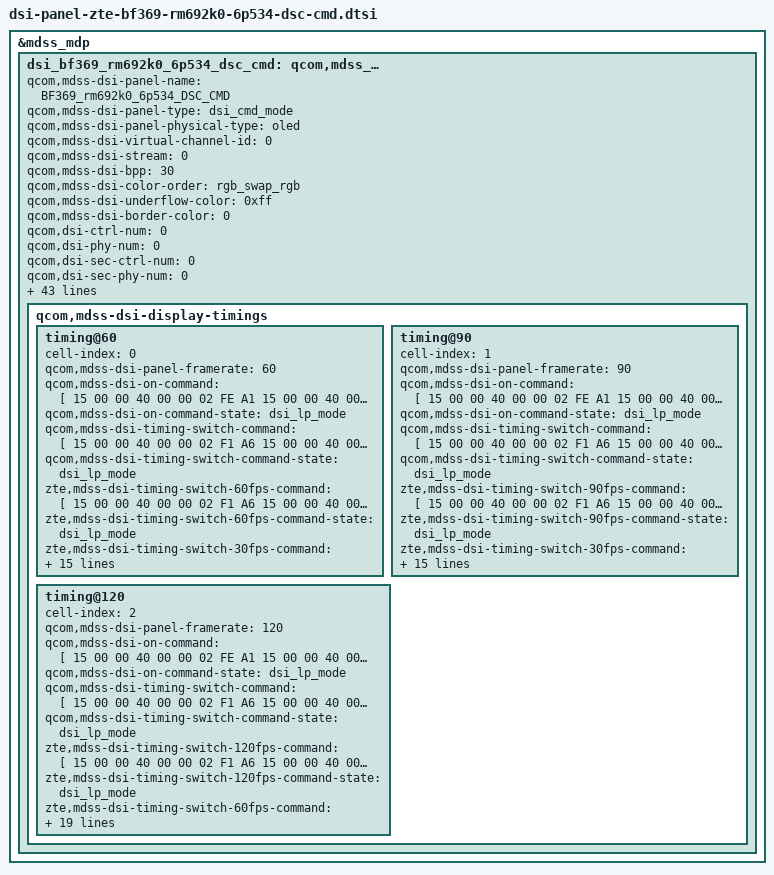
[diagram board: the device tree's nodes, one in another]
// SPDX-License-Identifier: BSD-3-Clause
/*
 * Copyright (c) 2023-2024 Qualcomm Innovation Center, Inc. All rights reserved.
 */

&mdss_mdp {
	dsi_bf369_rm692k0_6p534_dsc_cmd: qcom,mdss_dsi_bf369_rm692k0_6p534_dsc_cmd {
		qcom,mdss-dsi-panel-name =
				"BF369_rm692k0_6p534_DSC_CMD";
		qcom,mdss-dsi-panel-type = "dsi_cmd_mode";
		qcom,mdss-dsi-panel-physical-type = "oled";
		qcom,mdss-dsi-virtual-channel-id = <0>;
		qcom,mdss-dsi-stream = <0>;
		qcom,mdss-dsi-bpp = <30>;
		qcom,mdss-dsi-color-order = "rgb_swap_rgb";
		qcom,mdss-dsi-underflow-color = <0xff>;
		qcom,mdss-dsi-border-color = <0>;
		qcom,dsi-ctrl-num = <0>;
		qcom,dsi-phy-num = <0>;
		qcom,dsi-sec-ctrl-num = <0>;
		qcom,dsi-sec-phy-num = <0>;
		qcom,mdss-dsi-traffic-mode = "burst_mode";
		qcom,mdss-dsi-lane-map = "lane_map_0123";
		qcom,mdss-dsi-bllp-eof-power-mode;
		qcom,mdss-dsi-bllp-power-mode;
		qcom,mdss-dsi-lane-0-state;
		qcom,mdss-dsi-lane-1-state;
		qcom,mdss-dsi-lane-2-state;
		qcom,mdss-dsi-lane-3-state;
		qcom,mdss-dsi-lp11-init;
		qcom,mdss-dsi-tx-eot-append;
		qcom,mdss-dsi-dma-trigger = "trigger_sw";
		qcom,mdss-dsi-mdp-trigger = "none";
		qcom,mdss-dsi-reset-sequence = <1 10>, <0 10>, <1 40>;
		qcom,mdss-dsi-te-pin-select = <1>;
		qcom,mdss-dsi-te-dcs-command = <1>;
		qcom,mdss-dsi-te-check-enable;
		qcom,mdss-dsi-te-using-te-pin;
		qcom,mdss-dsi-bl-min-level = <1>;
		qcom,mdss-dsi-bl-max-level = <4095>;
		qcom,mdss-dsi-bl-pmic-control-type = "bl_ctrl_dcs";
		qcom,mdss-dsi-panel-hdr-enabled;
		qcom,mdss-dsi-panel-hdr-color-primaries = <14500 15500 34015
			15980 13030 34670 6950 2565>;
		qcom,mdss-dsi-panel-peak-brightness = <6680000>;
		qcom,mdss-dsi-panel-blackness-level = <20>;
		qcom,mdss-pan-physical-width-dimension = <72>;
		qcom,mdss-pan-physical-height-dimension = <158>;
		qcom,bl-dcs-cmd-state = "dsi_lp_mode";
		qcom,bl-dsc-cmd-state = "dsi_lp_mode";
		qcom,mdss-disable-cesta-hw-sleep;
		qcom,mdss-dsi-display-timings {
			timing@60 {
				cell-index = <0>;
				qcom,mdss-dsi-panel-framerate = <60>;
				#include "dsi-panel-zte-bf369-rm692k0-6p534-dsc-cmd-common.dtsi"
				qcom,mdss-dsi-on-command = [
					15 00 00 40 00 00 02 FE A1
					15 00 00 40 00 00 02 50 20
					15 00 00 40 00 00 02 FE A3
					15 00 00 40 00 00 02 00 01
					15 00 00 40 00 00 02 FE D0
					15 00 00 40 00 00 02 86 23
					15 00 00 40 00 00 02 84 23
					15 00 00 40 00 00 02 FE 99
					15 00 00 40 00 00 02 1B 23
					15 00 00 40 00 00 02 FE 44
					15 00 00 40 00 00 02 41 10
					15 00 00 40 00 00 02 3D 08
					15 00 00 40 00 00 02 08 32
					15 00 00 40 00 00 02 17 00
					15 00 00 40 00 00 02 18 06
					15 00 00 40 00 00 02 19 0F
					15 00 00 40 00 00 02 1F 44
					15 00 00 40 00 00 02 20 41
					15 00 00 40 00 00 02 FE FF
					15 00 00 40 00 00 02 63 1C
					15 00 00 40 00 00 02 64 1C
					15 00 00 40 00 00 02 65 1C
					15 00 00 40 00 00 02 66 1C
					15 00 00 40 00 00 02 6B 00
					15 00 00 40 00 00 02 6C 00
					15 00 00 40 00 00 02 6D 00
					15 00 00 40 00 00 02 6E 00
					15 00 00 40 00 00 02 FE E3
					15 00 00 00 00 00 02 73 80
					/* vesa */
					15 00 00 40 00 00 02 FE D2
					15 00 00 40 00 00 02 97 08
					15 00 00 40 00 00 02 FE A1
					15 00 00 40 00 00 02 75 B3
					15 00 00 40 00 00 02 FE D2
					15 00 00 40 00 00 02 36 11
					15 00 00 40 00 00 02 39 ab
					15 00 00 40 00 00 02 3a 30
					15 00 00 40 00 00 02 3b 80
					15 00 00 40 00 00 02 3d 0a
					15 00 00 40 00 00 02 3f bc
					15 00 00 40 00 00 02 40 04
					15 00 00 40 00 00 02 41 94
					15 00 00 40 00 00 02 42 00
					15 00 00 40 00 00 02 43 0c
					15 00 00 40 00 00 02 44 02
					15 00 00 40 00 00 02 45 4a
					15 00 00 40 00 00 02 46 02
					15 00 00 40 00 00 02 47 4a
					15 00 00 40 00 00 02 48 02
					15 00 00 40 00 00 02 49 00
					15 00 00 40 00 00 02 4a 02
					15 00 00 40 00 00 02 4b 26
					15 00 00 40 00 00 02 4d 20
					15 00 00 40 00 00 02 4e 01
					15 00 00 40 00 00 02 4f 2c
					15 00 00 40 00 00 02 50 00
					15 00 00 40 00 00 02 51 08
					15 00 00 40 00 00 02 53 0c
					15 00 00 40 00 00 02 54 08
					15 00 00 40 00 00 02 55 bb
					15 00 00 40 00 00 02 56 07
					15 00 00 40 00 00 02 58 c9
					15 00 00 40 00 00 02 59 18
					15 00 00 40 00 00 02 5a 00
					15 00 00 40 00 00 02 5b 10
					15 00 00 40 00 00 02 5c f0
					15 00 00 40 00 00 02 5d 07
					15 00 00 40 00 00 02 5e 10
					15 00 00 40 00 00 02 5f 20
					15 00 00 40 00 00 02 60 00
					15 00 00 40 00 00 02 61 06
					15 00 00 40 00 00 02 62 0f
					15 00 00 40 00 00 02 63 0f
					15 00 00 40 00 00 02 64 33
					15 00 00 40 00 00 02 65 0e
					15 00 00 40 00 00 02 66 1c
					15 00 00 40 00 00 02 67 2a
					15 00 00 40 00 00 02 68 38
					15 00 00 40 00 00 02 69 46
					15 00 00 40 00 00 02 6a 54
					15 00 00 40 00 00 02 6b 62
					15 00 00 40 00 00 02 6c 69
					15 00 00 40 00 00 02 6d 70
					15 00 00 40 00 00 02 6e 77
					15 00 00 40 00 00 02 6f 79
					15 00 00 40 00 00 02 70 7b
					15 00 00 40 00 00 02 71 7d
					15 00 00 40 00 00 02 72 7e
					15 00 00 40 00 00 02 73 02
					15 00 00 40 00 00 02 74 02
					15 00 00 40 00 00 02 75 22
					15 00 00 40 00 00 02 76 00
					15 00 00 40 00 00 02 77 2a
					15 00 00 40 00 00 02 78 40
					15 00 00 40 00 00 02 79 2a
					15 00 00 40 00 00 02 7a be
					15 00 00 40 00 00 02 7b 3a
					15 00 00 40 00 00 02 7c fc
					15 00 00 40 00 00 02 7d 3a
					15 00 00 40 00 00 02 7e fa
					15 00 00 40 00 00 02 7f 3a
					15 00 00 40 00 00 02 80 f8
					15 00 00 40 00 00 02 81 3b
					15 00 00 40 00 00 02 82 38
					15 00 00 40 00 00 02 83 3b
					15 00 00 40 00 00 02 84 78
					15 00 00 40 00 00 02 85 3b
					15 00 00 40 00 00 02 86 b6
					15 00 00 40 00 00 02 87 4b
					15 00 00 40 00 00 02 88 f6
					15 00 00 40 00 00 02 89 4c
					15 00 00 40 00 00 02 8a 34
					15 00 00 40 00 00 02 8b 4c
					15 00 00 40 00 00 02 8c 74
					15 00 00 40 00 00 02 8d 5c
					15 00 00 40 00 00 02 8e 74
					15 00 00 40 00 00 02 8f 8c
					15 00 00 40 00 00 02 90 f4
					15 00 00 40 00 00 02 91 00
					15 00 00 40 00 00 02 92 00
					15 00 00 40 00 00 02 93 00
					15 00 00 40 00 00 02 94 00
					15 00 00 40 00 00 02 95 00
					15 00 00 00 00 00 02 96 00
					/* add */
					15 00 00 00 00 00 02 FE A1
					15 00 00 00 00 00 02 58 67
					/* init code */
					15 00 00 00 00 00 02 FE 00
					15 00 00 00 00 00 02 2F 0C
					15 00 00 00 00 00 02 FA 01
					15 00 00 00 00 00 02 C2 08
					15 00 00 00 00 00 02 35 00
					39 00 00 00 00 00 03 51 00 00
					05 00 00 00 64 00 01 11
					05 00 00 00 14 00 01 29
					/* fps 60 */
					15 00 00 40 00 00 02 F1 A6
					15 00 00 40 00 00 02 FE 00
					15 00 00 40 00 00 02 6A 10
					15 00 00 40 00 00 02 8A 12
					15 00 00 40 00 00 02 FE 98
					15 00 00 40 00 00 02 37 92
					15 00 00 40 00 00 02 3B 0A
					15 00 00 40 00 00 02 FE 45
					15 00 00 40 00 00 02 B5 83
					15 00 00 40 00 00 02 B6 C0
					15 00 00 40 00 00 02 B7 30
					15 00 00 40 00 00 02 B8 5C
					15 00 00 40 00 00 02 B9 44
					15 00 00 40 00 00 02 BB 06
					15 00 00 40 00 00 02 BA 05
					15 00 00 40 00 00 02 BC 00
					15 00 00 40 00 00 02 BD 09
					15 00 00 00 12 00 02 FB AA
					15 00 00 00 00 00 02 FE 00
					];
				qcom,mdss-dsi-on-command-state = "dsi_lp_mode";
				qcom,mdss-dsi-timing-switch-command = [
					/* fps 60 */
					15 00 00 40 00 00 02 F1 A6
					15 00 00 40 00 00 02 FE 00
					15 00 00 40 00 00 02 6A 10
					15 00 00 40 00 00 02 8A 12
					15 00 00 40 00 00 02 FE 98
					15 00 00 40 00 00 02 37 92
					15 00 00 40 00 00 02 3B 0A
					15 00 00 40 00 00 02 FE 45
					15 00 00 40 00 00 02 B5 83
					15 00 00 40 00 00 02 B6 C0
					15 00 00 40 00 00 02 B7 30
					15 00 00 40 00 00 02 B8 5C
					15 00 00 40 00 00 02 B9 44
					15 00 00 40 00 00 02 BB 06
					15 00 00 40 00 00 02 BA 05
					15 00 00 40 00 00 02 BC 00
					15 00 00 40 00 00 02 BD 09
					15 00 00 00 12 00 02 FB AA
					15 00 00 00 00 00 02 FE 00
					];
				qcom,mdss-dsi-timing-switch-command-state = "dsi_lp_mode";
				zte,mdss-dsi-timing-switch-60fps-command = [
					/* fps 60 */
					15 00 00 40 00 00 02 F1 A6
					15 00 00 40 00 00 02 FE 00
					15 00 00 40 00 00 02 6A 10
					15 00 00 40 00 00 02 8A 12
					15 00 00 40 00 00 02 FE 98
					15 00 00 40 00 00 02 37 92
					15 00 00 40 00 00 02 3B 0A
					15 00 00 40 00 00 02 FE 45
					15 00 00 40 00 00 02 B5 83
					15 00 00 40 00 00 02 B6 C0
					15 00 00 40 00 00 02 B7 30
					15 00 00 40 00 00 02 B8 5C
					15 00 00 40 00 00 02 B9 44
					15 00 00 40 00 00 02 BB 06
					15 00 00 40 00 00 02 BA 05
					15 00 00 40 00 00 02 BC 00
					15 00 00 40 00 00 02 BD 09
					15 00 00 00 12 00 02 FB AA
					15 00 00 00 00 00 02 FE 00
				];
				zte,mdss-dsi-timing-switch-60fps-command-state = "dsi_lp_mode";
				zte,mdss-dsi-timing-switch-30fps-command = [
					/* fps 30 */
					15 00 00 40 00 00 02 F1 A6
					15 00 00 40 00 00 02 FE 00
					15 00 00 40 00 00 02 6A 10
					15 00 00 40 00 00 02 8A 1A
					15 00 00 40 00 00 02 FE 98
					15 00 00 40 00 00 02 37 92
					15 00 00 40 00 00 02 3B 0A
					15 00 00 40 00 00 02 FE 45
					15 00 00 40 00 00 02 B5 83
					15 00 00 40 00 00 02 B6 C0
					15 00 00 40 00 00 02 B7 30
					15 00 00 40 00 00 02 B8 5C
					15 00 00 40 00 00 02 B9 44
					15 00 00 40 00 00 02 BB 06
					15 00 00 40 00 00 02 BA 05
					15 00 00 40 00 00 02 BC 00
					15 00 00 40 00 00 02 BD 09
					15 00 00 00 12 00 02 FB AA
					15 00 00 00 00 00 02 FE 00
				];
				zte,mdss-dsi-timing-switch-30fps-command-state = "dsi_lp_mode";
				zte,mdss-dsi-timing-switch-10fps-command = [
					/* fps 10 */
					15 00 00 40 00 00 02 F1 A6
					15 00 00 40 00 00 02 FE 00
					15 00 00 40 00 00 02 6A 10
					15 00 00 40 00 00 02 8A 1B
					15 00 00 40 00 00 02 FE 98
					15 00 00 40 00 00 02 37 92
					15 00 00 40 00 00 02 3B 0A
					15 00 00 40 00 00 02 FE 45
					15 00 00 40 00 00 02 B5 83
					15 00 00 40 00 00 02 B6 C0
					15 00 00 40 00 00 02 B7 30
					15 00 00 40 00 00 02 B8 5C
					15 00 00 40 00 00 02 B9 44
					15 00 00 40 00 00 02 BB 06
					15 00 00 40 00 00 02 BA 05
					15 00 00 40 00 00 02 BC 00
					15 00 00 40 00 00 02 BD 09
					15 00 00 00 12 00 02 FB AA
					15 00 00 00 00 00 02 FE 00
				];
				zte,mdss-dsi-timing-switch-10fps-command-state = "dsi_lp_mode";
				zte,mdss-dsi-timing-switch-5fps-command = [
					/* fps 1 */
					15 00 00 40 00 00 02 F1 A6
					15 00 00 40 00 00 02 FE 00
					15 00 00 40 00 00 02 6A 10
					15 00 00 40 00 00 02 8A 1C
					15 00 00 40 00 00 02 FE 98
					15 00 00 40 00 00 02 37 92
					15 00 00 40 00 00 02 3B 0A
					15 00 00 40 00 00 02 FE 45
					15 00 00 40 00 00 02 B5 83
					15 00 00 40 00 00 02 B6 C0
					15 00 00 40 00 00 02 B7 30
					15 00 00 40 00 00 02 B8 5C
					15 00 00 40 00 00 02 B9 44
					15 00 00 40 00 00 02 BB 06
					15 00 00 40 00 00 02 BA 05
					15 00 00 40 00 00 02 BC 00
					15 00 00 40 00 00 02 BD 09
					15 00 00 00 12 00 02 FB AA
					15 00 00 00 00 00 02 FE 00
				];
				zte,mdss-dsi-timing-switch-5fps-command-state = "dsi_lp_mode";
				zte,mdss-dsi-timing-switch-1fps-command = [
					/* fps 1 */
					15 00 00 40 00 00 02 F1 A6
					15 00 00 40 00 00 02 FE 00
					15 00 00 40 00 00 02 6A 10
					15 00 00 40 00 00 02 8A 1D
					15 00 00 40 00 00 02 FE 98
					15 00 00 40 00 00 02 37 92
					15 00 00 40 00 00 02 3B 0A
					15 00 00 40 00 00 02 FE 45
					15 00 00 40 00 00 02 B5 83
					15 00 00 40 00 00 02 B6 C0
					15 00 00 40 00 00 02 B7 30
					15 00 00 40 00 00 02 B8 5C
					15 00 00 40 00 00 02 B9 45
					15 00 00 40 00 00 02 BB 06
					15 00 00 40 00 00 02 BA 05
					15 00 00 40 00 00 02 BC 00
					15 00 00 40 00 00 02 BD 09
					15 00 00 00 12 00 02 FB AA
					15 00 00 00 00 00 02 FE 00
				];
				zte,mdss-dsi-timing-switch-1fps-command-state = "dsi_lp_mode";
			};
			timing@90 {
				cell-index = <1>;
				qcom,mdss-dsi-panel-framerate = <90>;
				#include "dsi-panel-zte-bf369-rm692k0-6p534-dsc-cmd-common.dtsi"
				qcom,mdss-dsi-on-command = [
					15 00 00 40 00 00 02 FE A1
					15 00 00 40 00 00 02 50 20
					15 00 00 40 00 00 02 FE A3
					15 00 00 40 00 00 02 00 01
					15 00 00 40 00 00 02 FE D0
					15 00 00 40 00 00 02 86 23
					15 00 00 40 00 00 02 84 23
					15 00 00 40 00 00 02 FE 99
					15 00 00 40 00 00 02 1B 23
					15 00 00 40 00 00 02 FE 44
					15 00 00 40 00 00 02 41 10
					15 00 00 40 00 00 02 3D 08
					15 00 00 40 00 00 02 08 32
					15 00 00 40 00 00 02 17 00
					15 00 00 40 00 00 02 18 06
					15 00 00 40 00 00 02 19 0F
					15 00 00 40 00 00 02 1F 44
					15 00 00 40 00 00 02 20 41
					15 00 00 40 00 00 02 FE FF
					15 00 00 40 00 00 02 63 1C
					15 00 00 40 00 00 02 64 1C
					15 00 00 40 00 00 02 65 1C
					15 00 00 40 00 00 02 66 1C
					15 00 00 40 00 00 02 6B 00
					15 00 00 40 00 00 02 6C 00
					15 00 00 40 00 00 02 6D 00
					15 00 00 40 00 00 02 6E 00
					15 00 00 40 00 00 02 FE E3
					15 00 00 00 00 00 02 73 80
					/* vesa */
					15 00 00 40 00 00 02 FE D2
					15 00 00 40 00 00 02 97 08
					15 00 00 40 00 00 02 FE A1
					15 00 00 40 00 00 02 75 B3
					15 00 00 40 00 00 02 FE D2
					15 00 00 40 00 00 02 36 11
					15 00 00 40 00 00 02 39 ab
					15 00 00 40 00 00 02 3a 30
					15 00 00 40 00 00 02 3b 80
					15 00 00 40 00 00 02 3d 0a
					15 00 00 40 00 00 02 3f bc
					15 00 00 40 00 00 02 40 04
					15 00 00 40 00 00 02 41 94
					15 00 00 40 00 00 02 42 00
					15 00 00 40 00 00 02 43 0c
					15 00 00 40 00 00 02 44 02
					15 00 00 40 00 00 02 45 4a
					15 00 00 40 00 00 02 46 02
					15 00 00 40 00 00 02 47 4a
					15 00 00 40 00 00 02 48 02
					15 00 00 40 00 00 02 49 00
					15 00 00 40 00 00 02 4a 02
					15 00 00 40 00 00 02 4b 26
					15 00 00 40 00 00 02 4d 20
					15 00 00 40 00 00 02 4e 01
					15 00 00 40 00 00 02 4f 2c
					15 00 00 40 00 00 02 50 00
					15 00 00 40 00 00 02 51 08
					15 00 00 40 00 00 02 53 0c
					15 00 00 40 00 00 02 54 08
					15 00 00 40 00 00 02 55 bb
					15 00 00 40 00 00 02 56 07
					15 00 00 40 00 00 02 58 c9
					15 00 00 40 00 00 02 59 18
					15 00 00 40 00 00 02 5a 00
					15 00 00 40 00 00 02 5b 10
					15 00 00 40 00 00 02 5c f0
					15 00 00 40 00 00 02 5d 07
					15 00 00 40 00 00 02 5e 10
					15 00 00 40 00 00 02 5f 20
					15 00 00 40 00 00 02 60 00
					15 00 00 40 00 00 02 61 06
					15 00 00 40 00 00 02 62 0f
					15 00 00 40 00 00 02 63 0f
					15 00 00 40 00 00 02 64 33
					15 00 00 40 00 00 02 65 0e
					15 00 00 40 00 00 02 66 1c
					15 00 00 40 00 00 02 67 2a
					15 00 00 40 00 00 02 68 38
					15 00 00 40 00 00 02 69 46
					15 00 00 40 00 00 02 6a 54
					15 00 00 40 00 00 02 6b 62
					15 00 00 40 00 00 02 6c 69
					15 00 00 40 00 00 02 6d 70
					15 00 00 40 00 00 02 6e 77
					15 00 00 40 00 00 02 6f 79
					15 00 00 40 00 00 02 70 7b
					15 00 00 40 00 00 02 71 7d
					15 00 00 40 00 00 02 72 7e
					15 00 00 40 00 00 02 73 02
					15 00 00 40 00 00 02 74 02
					15 00 00 40 00 00 02 75 22
					15 00 00 40 00 00 02 76 00
					15 00 00 40 00 00 02 77 2a
					15 00 00 40 00 00 02 78 40
					15 00 00 40 00 00 02 79 2a
					15 00 00 40 00 00 02 7a be
					15 00 00 40 00 00 02 7b 3a
					15 00 00 40 00 00 02 7c fc
					15 00 00 40 00 00 02 7d 3a
					15 00 00 40 00 00 02 7e fa
					15 00 00 40 00 00 02 7f 3a
					15 00 00 40 00 00 02 80 f8
					15 00 00 40 00 00 02 81 3b
					15 00 00 40 00 00 02 82 38
					15 00 00 40 00 00 02 83 3b
					15 00 00 40 00 00 02 84 78
					15 00 00 40 00 00 02 85 3b
					15 00 00 40 00 00 02 86 b6
					15 00 00 40 00 00 02 87 4b
					15 00 00 40 00 00 02 88 f6
					15 00 00 40 00 00 02 89 4c
					15 00 00 40 00 00 02 8a 34
					15 00 00 40 00 00 02 8b 4c
					15 00 00 40 00 00 02 8c 74
					15 00 00 40 00 00 02 8d 5c
					15 00 00 40 00 00 02 8e 74
					15 00 00 40 00 00 02 8f 8c
					15 00 00 40 00 00 02 90 f4
					15 00 00 40 00 00 02 91 00
					15 00 00 40 00 00 02 92 00
					15 00 00 40 00 00 02 93 00
					15 00 00 40 00 00 02 94 00
					15 00 00 40 00 00 02 95 00
					15 00 00 00 00 00 02 96 00
					/* add */
					15 00 00 00 00 00 02 FE A1
					15 00 00 00 00 00 02 58 67
					/* init code */
					15 00 00 00 00 00 02 FE 00
					15 00 00 00 00 00 02 2F 0C
					15 00 00 00 00 00 02 FA 01
					15 00 00 00 00 00 02 C2 08
					15 00 00 00 00 00 02 35 00
					39 00 00 00 00 00 03 51 00 00
					05 00 00 00 64 00 01 11
					05 00 00 00 14 00 01 29
					/* fps 90 */
					15 00 00 40 00 00 02 F1 A6
					15 00 00 40 00 00 02 FE 00
					15 00 00 40 00 00 02 6A 10
					15 00 00 40 00 00 02 8A 11
					15 00 00 40 00 00 02 FE 98
					15 00 00 40 00 00 02 37 92
					15 00 00 40 00 00 02 3B 0A
					15 00 00 40 00 00 02 FE 45
					15 00 00 40 00 00 02 B5 83
					15 00 00 40 00 00 02 B6 C0
					15 00 00 40 00 00 02 B7 30
					15 00 00 40 00 00 02 B8 5C
					15 00 00 40 00 00 02 B9 44
					15 00 00 40 00 00 02 BB 06
					15 00 00 40 00 00 02 BA 03
					15 00 00 40 00 00 02 BC 00
					15 00 00 40 00 00 02 BD 09
					15 00 00 00 12 00 02 FB AA
					15 00 00 00 00 00 02 FE 00
					];
				qcom,mdss-dsi-on-command-state = "dsi_lp_mode";
				qcom,mdss-dsi-timing-switch-command = [
					/* fps 90 */
					15 00 00 40 00 00 02 F1 A6
					15 00 00 40 00 00 02 FE 00
					15 00 00 40 00 00 02 6A 10
					15 00 00 40 00 00 02 8A 11
					15 00 00 40 00 00 02 FE 98
					15 00 00 40 00 00 02 3B 0A
					15 00 00 40 00 00 02 FE 45
					15 00 00 40 00 00 02 B5 83
					15 00 00 40 00 00 02 B6 C0
					15 00 00 40 00 00 02 B7 30
					15 00 00 40 00 00 02 B8 5C
					15 00 00 40 00 00 02 B9 44
					15 00 00 40 00 00 02 BB 06
					15 00 00 40 00 00 02 BA 03
					15 00 00 40 00 00 02 BC 00
					15 00 00 40 00 00 02 BD 09
					15 00 00 00 12 00 02 FB AA
					15 00 00 00 00 00 02 FE 00
					];
				qcom,mdss-dsi-timing-switch-command-state = "dsi_lp_mode";
				zte,mdss-dsi-timing-switch-90fps-command = [
					/* fps 90 */
					15 00 00 40 00 00 02 F1 A6
					15 00 00 40 00 00 02 FE 00
					15 00 00 40 00 00 02 6A 10
					15 00 00 40 00 00 02 8A 11
					15 00 00 40 00 00 02 FE 98
					15 00 00 40 00 00 02 3B 0A
					15 00 00 40 00 00 02 FE 45
					15 00 00 40 00 00 02 B5 83
					15 00 00 40 00 00 02 B6 C0
					15 00 00 40 00 00 02 B7 30
					15 00 00 40 00 00 02 B8 5C
					15 00 00 40 00 00 02 B9 44
					15 00 00 40 00 00 02 BB 06
					15 00 00 40 00 00 02 BA 03
					15 00 00 40 00 00 02 BC 00
					15 00 00 40 00 00 02 BD 09
					15 00 00 00 12 00 02 FB AA
					15 00 00 00 00 00 02 FE 00
				];
				zte,mdss-dsi-timing-switch-90fps-command-state = "dsi_lp_mode";
				zte,mdss-dsi-timing-switch-30fps-command = [
					/* fps 30 */
					15 00 00 40 00 00 02 F1 A6
					15 00 00 40 00 00 02 FE 00
					15 00 00 40 00 00 02 6A 10
					15 00 00 40 00 00 02 8A 1A
					15 00 00 40 00 00 02 FE 98
					15 00 00 40 00 00 02 37 92
					15 00 00 40 00 00 02 3B 0A
					15 00 00 40 00 00 02 FE 45
					15 00 00 40 00 00 02 B5 83
					15 00 00 40 00 00 02 B6 C0
					15 00 00 40 00 00 02 B7 30
					15 00 00 40 00 00 02 B8 5C
					15 00 00 40 00 00 02 B9 44
					15 00 00 40 00 00 02 BB 04
					15 00 00 40 00 00 02 BA 03
					15 00 00 40 00 00 02 BC 00
					15 00 00 40 00 00 02 BD 09
					15 00 00 00 12 00 02 FB AA
					15 00 00 00 00 00 02 FE 00
				];
				zte,mdss-dsi-timing-switch-30fps-command-state = "dsi_lp_mode";
				zte,mdss-dsi-timing-switch-10fps-command = [
					/* fps 10 */
					15 00 00 40 00 00 02 F1 A6
					15 00 00 40 00 00 02 FE 00
					15 00 00 40 00 00 02 6A 10
					15 00 00 40 00 00 02 8A 1B
					15 00 00 40 00 00 02 FE 98
					15 00 00 40 00 00 02 37 92
					15 00 00 40 00 00 02 3B 0A
					15 00 00 40 00 00 02 FE 45
					15 00 00 40 00 00 02 B5 83
					15 00 00 40 00 00 02 B6 C0
					15 00 00 40 00 00 02 B7 30
					15 00 00 40 00 00 02 B8 5C
					15 00 00 40 00 00 02 B9 44
					15 00 00 40 00 00 02 BB 04
					15 00 00 40 00 00 02 BA 03
					15 00 00 40 00 00 02 BC 00
					15 00 00 40 00 00 02 BD 09
					15 00 00 00 12 00 02 FB AA
					15 00 00 00 00 00 02 FE 00
				];
				zte,mdss-dsi-timing-switch-10fps-command-state = "dsi_lp_mode";
				zte,mdss-dsi-timing-switch-5fps-command = [
					/* fps 1 */
					15 00 00 40 00 00 02 F1 A6
					15 00 00 40 00 00 02 FE 00
					15 00 00 40 00 00 02 6A 10
					15 00 00 40 00 00 02 8A 1C
					15 00 00 40 00 00 02 FE 98
					15 00 00 40 00 00 02 37 92
					15 00 00 40 00 00 02 3B 0A
					15 00 00 40 00 00 02 FE 45
					15 00 00 40 00 00 02 B5 83
					15 00 00 40 00 00 02 B6 C0
					15 00 00 40 00 00 02 B7 30
					15 00 00 40 00 00 02 B8 5C
					15 00 00 40 00 00 02 B9 44
					15 00 00 40 00 00 02 BB 04
					15 00 00 40 00 00 02 BA 03
					15 00 00 40 00 00 02 BC 00
					15 00 00 40 00 00 02 BD 09
					15 00 00 00 12 00 02 FB AA
					15 00 00 00 00 00 02 FE 00
				];
				zte,mdss-dsi-timing-switch-5fps-command-state = "dsi_lp_mode";
				zte,mdss-dsi-timing-switch-1fps-command = [
					/* fps 1 */
					15 00 00 40 00 00 02 F1 A6
					15 00 00 40 00 00 02 FE 00
					15 00 00 40 00 00 02 6A 10
					15 00 00 40 00 00 02 8A 1D
					15 00 00 40 00 00 02 FE 98
					15 00 00 40 00 00 02 37 92
					15 00 00 40 00 00 02 3B 0A
					15 00 00 40 00 00 02 FE 45
					15 00 00 40 00 00 02 B5 83
					15 00 00 40 00 00 02 B6 C0
					15 00 00 40 00 00 02 B7 30
					15 00 00 40 00 00 02 B8 5C
					15 00 00 40 00 00 02 B9 44
					15 00 00 40 00 00 02 BB 04
					15 00 00 40 00 00 02 BA 03
					15 00 00 40 00 00 02 BC 00
					15 00 00 40 00 00 02 BD 09
					15 00 00 00 12 00 02 FB AA
					15 00 00 00 00 00 02 FE 00
				];
				zte,mdss-dsi-timing-switch-1fps-command-state = "dsi_lp_mode";
			};
			timing@120 {
				cell-index = <2>;
				qcom,mdss-dsi-panel-framerate = <120>;
				#include "dsi-panel-zte-bf369-rm692k0-6p534-dsc-cmd-common.dtsi"
				qcom,mdss-dsi-on-command = [
					15 00 00 40 00 00 02 FE A1
					15 00 00 40 00 00 02 50 20
					15 00 00 40 00 00 02 FE A3
					15 00 00 40 00 00 02 00 01
					15 00 00 40 00 00 02 FE D0
					15 00 00 40 00 00 02 86 23
					15 00 00 40 00 00 02 84 23
					15 00 00 40 00 00 02 FE 99
					15 00 00 40 00 00 02 1B 23
					15 00 00 40 00 00 02 FE 44
					15 00 00 40 00 00 02 41 10
					15 00 00 40 00 00 02 3D 08
					15 00 00 40 00 00 02 08 32
					15 00 00 40 00 00 02 17 00
					15 00 00 40 00 00 02 18 06
					15 00 00 40 00 00 02 19 0F
					15 00 00 40 00 00 02 1F 44
					15 00 00 40 00 00 02 20 41
					15 00 00 40 00 00 02 FE FF
					15 00 00 40 00 00 02 63 1C
					15 00 00 40 00 00 02 64 1C
					15 00 00 40 00 00 02 65 1C
					15 00 00 40 00 00 02 66 1C
					15 00 00 40 00 00 02 6B 00
					15 00 00 40 00 00 02 6C 00
					15 00 00 40 00 00 02 6D 00
					15 00 00 40 00 00 02 6E 00
					15 00 00 40 00 00 02 FE E3
					15 00 00 00 00 00 02 73 80
					/* vesa */
					15 00 00 40 00 00 02 FE D2
					15 00 00 40 00 00 02 97 08
					15 00 00 40 00 00 02 FE A1
					15 00 00 40 00 00 02 75 B3
					15 00 00 40 00 00 02 FE D2
					15 00 00 40 00 00 02 36 11
					15 00 00 40 00 00 02 39 ab
					15 00 00 40 00 00 02 3a 30
					15 00 00 40 00 00 02 3b 80
					15 00 00 40 00 00 02 3d 0a
					15 00 00 40 00 00 02 3f bc
					15 00 00 40 00 00 02 40 04
					15 00 00 40 00 00 02 41 94
					15 00 00 40 00 00 02 42 00
					15 00 00 40 00 00 02 43 0c
					15 00 00 40 00 00 02 44 02
					15 00 00 40 00 00 02 45 4a
					15 00 00 40 00 00 02 46 02
					15 00 00 40 00 00 02 47 4a
					15 00 00 40 00 00 02 48 02
					15 00 00 40 00 00 02 49 00
					15 00 00 40 00 00 02 4a 02
					15 00 00 40 00 00 02 4b 26
					15 00 00 40 00 00 02 4d 20
					15 00 00 40 00 00 02 4e 01
					15 00 00 40 00 00 02 4f 2c
					15 00 00 40 00 00 02 50 00
					15 00 00 40 00 00 02 51 08
					15 00 00 40 00 00 02 53 0c
					15 00 00 40 00 00 02 54 08
					15 00 00 40 00 00 02 55 bb
					15 00 00 40 00 00 02 56 07
					15 00 00 40 00 00 02 58 c9
					15 00 00 40 00 00 02 59 18
					15 00 00 40 00 00 02 5a 00
					15 00 00 40 00 00 02 5b 10
					15 00 00 40 00 00 02 5c f0
					15 00 00 40 00 00 02 5d 07
					15 00 00 40 00 00 02 5e 10
					15 00 00 40 00 00 02 5f 20
					15 00 00 40 00 00 02 60 00
					15 00 00 40 00 00 02 61 06
					15 00 00 40 00 00 02 62 0f
					15 00 00 40 00 00 02 63 0f
					15 00 00 40 00 00 02 64 33
					15 00 00 40 00 00 02 65 0e
					15 00 00 40 00 00 02 66 1c
					15 00 00 40 00 00 02 67 2a
					15 00 00 40 00 00 02 68 38
					15 00 00 40 00 00 02 69 46
					15 00 00 40 00 00 02 6a 54
					15 00 00 40 00 00 02 6b 62
					15 00 00 40 00 00 02 6c 69
					15 00 00 40 00 00 02 6d 70
					15 00 00 40 00 00 02 6e 77
					15 00 00 40 00 00 02 6f 79
					15 00 00 40 00 00 02 70 7b
					15 00 00 40 00 00 02 71 7d
					15 00 00 40 00 00 02 72 7e
					15 00 00 40 00 00 02 73 02
					15 00 00 40 00 00 02 74 02
					15 00 00 40 00 00 02 75 22
					15 00 00 40 00 00 02 76 00
					15 00 00 40 00 00 02 77 2a
					15 00 00 40 00 00 02 78 40
					15 00 00 40 00 00 02 79 2a
					15 00 00 40 00 00 02 7a be
					15 00 00 40 00 00 02 7b 3a
					15 00 00 40 00 00 02 7c fc
					15 00 00 40 00 00 02 7d 3a
					15 00 00 40 00 00 02 7e fa
					15 00 00 40 00 00 02 7f 3a
					15 00 00 40 00 00 02 80 f8
					15 00 00 40 00 00 02 81 3b
					15 00 00 40 00 00 02 82 38
					15 00 00 40 00 00 02 83 3b
					15 00 00 40 00 00 02 84 78
					15 00 00 40 00 00 02 85 3b
					15 00 00 40 00 00 02 86 b6
					15 00 00 40 00 00 02 87 4b
					15 00 00 40 00 00 02 88 f6
					15 00 00 40 00 00 02 89 4c
					15 00 00 40 00 00 02 8a 34
					15 00 00 40 00 00 02 8b 4c
					15 00 00 40 00 00 02 8c 74
					15 00 00 40 00 00 02 8d 5c
					15 00 00 40 00 00 02 8e 74
					15 00 00 40 00 00 02 8f 8c
					15 00 00 40 00 00 02 90 f4
					15 00 00 40 00 00 02 91 00
					15 00 00 40 00 00 02 92 00
					15 00 00 40 00 00 02 93 00
					15 00 00 40 00 00 02 94 00
					15 00 00 40 00 00 02 95 00
					15 00 00 00 00 00 02 96 00
					/* add */
					15 00 00 00 00 00 02 FE A1
					15 00 00 00 00 00 02 58 67
					/* init code */
					15 00 00 00 00 00 02 FE 00
					15 00 00 00 00 00 02 2F 0C
					15 00 00 00 00 00 02 FA 01
					15 00 00 00 00 00 02 C2 08
					15 00 00 00 00 00 02 35 00
					39 00 00 00 00 00 03 51 00 00
					05 00 00 00 64 00 01 11
					05 00 00 00 14 00 01 29
					/* fps 120 */
					15 00 00 40 00 00 02 F1 A6
					15 00 00 40 00 00 02 FE 00
					15 00 00 40 00 00 02 6A 10
					15 00 00 40 00 00 02 8A 10
					15 00 00 40 00 00 02 FE 98
					15 00 00 40 00 00 02 3B 0A
					15 00 00 40 00 00 02 FE 45
					15 00 00 40 00 00 02 B5 83
					15 00 00 40 00 00 02 B6 C0
					15 00 00 40 00 00 02 B7 30
					15 00 00 40 00 00 02 B8 5C
					15 00 00 40 00 00 02 B9 44
					15 00 00 40 00 00 02 BB 06
					15 00 00 40 00 00 02 BA 02
					15 00 00 40 00 00 02 BC 00
					15 00 00 40 00 00 02 BD 09
					15 00 00 00 12 00 02 FB AA
					15 00 00 00 00 00 02 FE 00
					];
				qcom,mdss-dsi-on-command-state = "dsi_lp_mode";
				qcom,mdss-dsi-timing-switch-command = [
					/* fps 120 */
					15 00 00 40 00 00 02 F1 A6
					15 00 00 40 00 00 02 FE 00
					15 00 00 40 00 00 02 6A 10
					15 00 00 40 00 00 02 8A 10
					15 00 00 40 00 00 02 FE 98
					15 00 00 40 00 00 02 37 92
					15 00 00 40 00 00 02 3B 0A
					15 00 00 40 00 00 02 FE 45
					15 00 00 40 00 00 02 B5 83
					15 00 00 40 00 00 02 B6 C0
					15 00 00 40 00 00 02 B7 30
					15 00 00 40 00 00 02 B8 5C
					15 00 00 40 00 00 02 B9 44
					15 00 00 40 00 00 02 BB 06
					15 00 00 40 00 00 02 BA 02
					15 00 00 40 00 00 02 BC 00
					15 00 00 40 00 00 02 BD 09
					15 00 00 00 12 00 02 FB AA
					15 00 00 00 00 00 02 FE 00
					];
				qcom,mdss-dsi-timing-switch-command-state = "dsi_lp_mode";
				zte,mdss-dsi-timing-switch-120fps-command = [
					/* fps 120 */
					15 00 00 40 00 00 02 F1 A6
					15 00 00 40 00 00 02 FE 00
					15 00 00 40 00 00 02 6A 10
					15 00 00 40 00 00 02 8A 10
					15 00 00 40 00 00 02 FE 98
					15 00 00 40 00 00 02 37 92
					15 00 00 40 00 00 02 3B 0A
					15 00 00 40 00 00 02 FE 45
					15 00 00 40 00 00 02 B5 83
					15 00 00 40 00 00 02 B6 C0
					15 00 00 40 00 00 02 B7 30
					15 00 00 40 00 00 02 B8 5C
					15 00 00 40 00 00 02 B9 44
					15 00 00 40 00 00 02 BB 06
					15 00 00 40 00 00 02 BA 02
					15 00 00 40 00 00 02 BC 00
					15 00 00 40 00 00 02 BD 09
					15 00 00 00 12 00 02 FB AA
					15 00 00 00 00 00 02 FE 00
				];
				zte,mdss-dsi-timing-switch-120fps-command-state = "dsi_lp_mode";
				zte,mdss-dsi-timing-switch-60fps-command = [
					/* fps 120 */
					15 00 00 40 00 00 02 F1 A6
					15 00 00 40 00 00 02 FE 00
					15 00 00 40 00 00 02 6A 10
					15 00 00 40 00 00 02 8A 12
					15 00 00 40 00 00 02 FE 98
					15 00 00 40 00 00 02 37 92
					15 00 00 40 00 00 02 3B 0A
					15 00 00 40 00 00 02 FE 45
					15 00 00 40 00 00 02 B5 83
					15 00 00 40 00 00 02 B6 C0
					15 00 00 40 00 00 02 B7 30
					15 00 00 40 00 00 02 B8 5C
					15 00 00 40 00 00 02 B9 44
					15 00 00 40 00 00 02 BB 03
					15 00 00 40 00 00 02 BA 02
					15 00 00 40 00 00 02 BC 00
					15 00 00 40 00 00 02 BD 09
					15 00 00 00 12 00 02 FB AA
					15 00 00 00 00 00 02 FE 00
				];
				zte,mdss-dsi-timing-switch-60fps-command-state = "dsi_lp_mode";
				zte,mdss-dsi-timing-switch-30fps-command = [
					/* fps 30 */
					15 00 00 40 00 00 02 F1 A6
					15 00 00 40 00 00 02 FE 00
					15 00 00 40 00 00 02 6A 10
					15 00 00 40 00 00 02 8A 1A
					15 00 00 40 00 00 02 FE 98
					15 00 00 40 00 00 02 37 92
					15 00 00 40 00 00 02 3B 0A
					15 00 00 40 00 00 02 FE 45
					15 00 00 40 00 00 02 B5 83
					15 00 00 40 00 00 02 B6 C0
					15 00 00 40 00 00 02 B7 30
					15 00 00 40 00 00 02 B8 5C
					15 00 00 40 00 00 02 B9 44
					15 00 00 40 00 00 02 BB 03
					15 00 00 40 00 00 02 BA 02
					15 00 00 40 00 00 02 BC 00
					15 00 00 40 00 00 02 BD 09
					15 00 00 00 12 00 02 FB AA
					15 00 00 00 00 00 02 FE 00
				];
				zte,mdss-dsi-timing-switch-30fps-command-state = "dsi_lp_mode";
				zte,mdss-dsi-timing-switch-10fps-command = [
					/* fps 10 */
					15 00 00 40 00 00 02 F1 A6
					15 00 00 40 00 00 02 FE 00
					15 00 00 40 00 00 02 6A 10
					15 00 00 40 00 00 02 8A 1B
					15 00 00 40 00 00 02 FE 98
					15 00 00 40 00 00 02 37 92
					15 00 00 40 00 00 02 3B 0A
					15 00 00 40 00 00 02 FE 45
					15 00 00 40 00 00 02 B5 83
					15 00 00 40 00 00 02 B6 C0
					15 00 00 40 00 00 02 B7 30
					15 00 00 40 00 00 02 B8 5C
					15 00 00 40 00 00 02 B9 44
					15 00 00 40 00 00 02 BB 03
					15 00 00 40 00 00 02 BA 02
					15 00 00 40 00 00 02 BC 00
					15 00 00 40 00 00 02 BD 09
					15 00 00 00 12 00 02 FB AA
					15 00 00 00 00 00 02 FE 00
				];
				zte,mdss-dsi-timing-switch-10fps-command-state = "dsi_lp_mode";
				zte,mdss-dsi-timing-switch-5fps-command = [
					/* fps 1 */
					15 00 00 40 00 00 02 F1 A6
					15 00 00 40 00 00 02 FE 00
					15 00 00 40 00 00 02 6A 10
					15 00 00 40 00 00 02 8A 1C
					15 00 00 40 00 00 02 FE 98
					15 00 00 40 00 00 02 37 92
					15 00 00 40 00 00 02 3B 0A
					15 00 00 40 00 00 02 FE 45
					15 00 00 40 00 00 02 B5 83
					15 00 00 40 00 00 02 B6 C0
					15 00 00 40 00 00 02 B7 30
					15 00 00 40 00 00 02 B8 5C
					15 00 00 40 00 00 02 B9 44
					15 00 00 40 00 00 02 BB 02
					15 00 00 40 00 00 02 BA 02
					15 00 00 40 00 00 02 BC 00
					15 00 00 40 00 00 02 BD 09
					15 00 00 00 12 00 02 FB AA
					15 00 00 00 00 00 02 FE 00
				];
				zte,mdss-dsi-timing-switch-5fps-command-state = "dsi_lp_mode";
				zte,mdss-dsi-timing-switch-1fps-command = [
					/* fps 1 */
					15 00 00 40 00 00 02 F1 A6
					15 00 00 40 00 00 02 FE 00
					15 00 00 40 00 00 02 6A 10
					15 00 00 40 00 00 02 8A 1D
					15 00 00 40 00 00 02 FE 98
					15 00 00 40 00 00 02 37 92
					15 00 00 40 00 00 02 3B 0A
					15 00 00 40 00 00 02 FE 45
					15 00 00 40 00 00 02 B5 83
					15 00 00 40 00 00 02 B6 C0
					15 00 00 40 00 00 02 B7 30
					15 00 00 40 00 00 02 B8 5C
					15 00 00 40 00 00 02 B9 44
					15 00 00 40 00 00 02 BB 03
					15 00 00 40 00 00 02 BA 02
					15 00 00 40 00 00 02 BC 00
					15 00 00 40 00 00 02 BD 09
					15 00 00 00 12 00 02 FB AA
					15 00 00 00 00 00 02 FE 00
				];
				zte,mdss-dsi-timing-switch-1fps-command-state = "dsi_lp_mode";
			};
		};
	};
};

/* zte dsip power supply */
&dsi_bf369_rm692k0_6p534_dsc_cmd {
	qcom,panel-supply-entries = <&dsi_panel_sec_pwr_supply>;
	qcom,panel-sec-supply-entries = <&dsi_panel_sec_pwr_supply>;
	qcom,mdss-dsi-bl-pmic-control-type = "bl_ctrl_dcs";
	qcom,mdss-dsi-sec-bl-pmic-control-type = "bl_ctrl_dcs";
	qcom,mdss-brightness-max-level = <4095>;
	qcom,mdss-dsi-bl-inverted-dbv;
	qcom,platform-sec-reset-gpio = <&tlmm 97 0>;
	qcom,ulps-enabled;
	qcom,dsi-select-sec-clocks = "pll_byte_clk0", "pll_dsi_clk0";
};
